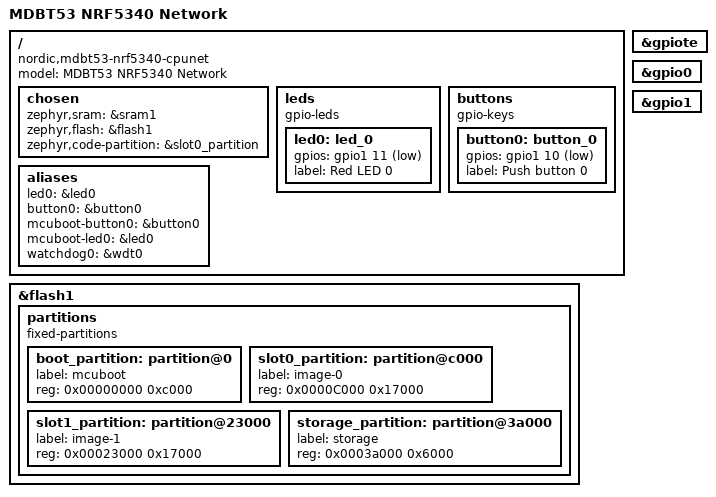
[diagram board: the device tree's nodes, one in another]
/*
 * Copyright (c) 2020 Nordic Semiconductor ASA
 *
 * SPDX-License-Identifier: Apache-2.0
 */

/dts-v1/;
#include <nordic/nrf5340_cpunet_qkaa.dtsi>
#include "mdbt53_nrf5340_cpunet-pinctrl.dtsi"

/ {
	model = "MDBT53 NRF5340 Network";
	compatible = "nordic,mdbt53-nrf5340-cpunet";

	chosen {
		zephyr,sram = &sram1;
		zephyr,flash = &flash1;
		zephyr,code-partition = &slot0_partition;
	};

	leds {
		compatible = "gpio-leds";
		led0: led_0 {
			gpios = <&gpio1 11 GPIO_ACTIVE_LOW>;
			label = "Red LED 0";
		};
	};

	buttons {
		compatible = "gpio-keys";
		button0: button_0 {
			gpios = <&gpio1 10 GPIO_ACTIVE_LOW>;
			label = "Push button 0";
		};
	};

	/* These aliases are provided for compatibility with samples */
	aliases {
		led0 = &led0;
		button0 = &button0;
		mcuboot-button0 = &button0;
		mcuboot-led0 = &led0;
		watchdog0 = &wdt0;
	};
};

&gpiote {
	status = "okay";
};

&gpio0 {
	status = "okay";
};

&gpio1 {
	status = "okay";
};

&flash1 {

	partitions {
		compatible = "fixed-partitions";
		#address-cells = <1>;
		#size-cells = <1>;

		boot_partition: partition@0 {
			label = "mcuboot";
			reg = <0x00000000 0xc000>;
		};
		slot0_partition: partition@c000 {
			label = "image-0";
			reg = <0x0000C000 0x17000>;
		};
		slot1_partition: partition@23000 {
			label = "image-1";
			reg = <0x00023000 0x17000>;
		};
		storage_partition: partition@3a000 {
			label = "storage";
			reg = <0x0003a000 0x6000>;
		};
	};
};

/* Include shared RAM configuration file */
#include "mdbt53_nrf5340_shared_sram_planning_conf.dtsi"
